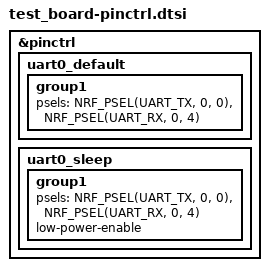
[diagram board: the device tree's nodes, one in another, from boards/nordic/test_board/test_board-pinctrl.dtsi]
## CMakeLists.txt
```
cmake_minimum_required(VERSION 3.20.0)

list(APPEND OVERLAY_CONFIG "$ENV{ZEPHYR_BASE}/../modules/lib/onomondo-softsim/overlay-softsim.conf")

find_package(Zephyr REQUIRED HINTS $ENV{ZEPHYR_BASE})

project(softsim_test)

target_sources(app PRIVATE src/main.c)
```

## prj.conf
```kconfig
### Onomondo SoftSIM ###
CONFIG_SOFTSIM_DEBUG=n
CONFIG_SOFTSIM_LOG_LEVEL_ERR=y
CONFIG_SOFTSIM_STATIC_PROFILE_ENABLE=y
# GSMA TS.48 USIM profile (standard test profile) replace with actual Onomondo profile
CONFIG_SOFTSIM_STATIC_PROFILE="01120829430512209610050214985437000000138663300320EF7A505140A7E8A25EA5368B52778CF70420E7DBC68622AB142A9C33881E20F42C5E0520B005031406ACF35099E61672E41747D10620D83BF18DA592DEC23855E83BC1A2BF340808393536310b1038353830343436370a2035393036333638383933383032333534"
### Onomondo SoftSIM ###

# Log Configurations
CONFIG_DEBUG=n
CONFIG_LOG=y
CONFIG_NRF_MODEM_LOG=n

# General Configurations
CONFIG_LOG_BUFFER_SIZE=5000
CONFIG_LOG_PROCESS_TRIGGER_THRESHOLD=5
CONFIG_LOG_DEFAULT_LEVEL=1

# Modem Configurations
CONFIG_NRF_MODEM_LIB=y

# NET Configurations
CONFIG_NETWORKING=y
CONFIG_NET_SOCKETS=y
CONFIG_NET_NATIVE=n
CONFIG_NET_SOCKETS_OFFLOAD=y
CONFIG_NET_SOCKETS_POSIX_NAMES=y

# LTE Configurations
CONFIG_LTE_LINK_CONTROL=y
CONFIG_LTE_LC_PSM_MODULE=y
CONFIG_LTE_LC_EDRX_MODULE=y
# Enable the neighbor cell measurement module to use the modem's neighbor cell measurement features
CONFIG_LTE_LC_NEIGHBOR_CELL_MEAS_MODULE=y
# Enable the LTE link control module to use the modem's PSM and eDRX features
CONFIG_LTE_PSM_REQ=y
CONFIG_LTE_EDRX_REQ=y

# AT host library
CONFIG_SERIAL=n
CONFIG_AT_HOST_LIBRARY=n
CONFIG_UART_INTERRUPT_DRIVEN=n

# Reduce the size of TF-M by disabling the PS
CONFIG_TFM_PARTITION_PROTECTED_STORAGE=n
CONFIG_PSA_CRYPTO_DRIVER_CC3XX=n

# Reduce the size of the TF-M partition
# when combined with static partitioning
CONFIG_PM_PARTITION_SIZE_TFM=0x10000

# The bootloader adds a small mcuboot_pad partition,
# whose size must be subtracted from the TF-M partition
#CONFIG_BOOTLOADER_MCUBOOT=y
#CONFIG_PM_PARTITION_SIZE_TFM=0xFE00

# Enable Segger RTT
CONFIG_USE_SEGGER_RTT=y

# Set RTT as the Zephyr logging backend
CONFIG_LOG_BACKEND_RTT=y

# Optional: Disable UART logging if you only want RTT
CONFIG_LOG_BACKEND_UART=n

# Increase RTT buffer size (if needed for large logs)
CONFIG_SEGGER_RTT_BUFFER_SIZE_UP=1024

# GNSS Configuration
CONFIG_LTE_NETWORK_MODE_LTE_M_NBIOT_GPS=y
# Newlib
# CONFIG_NEWLIB_LIBC=y
# # Enable printing of floating-points
# CONFIG_NEWLIB_LIBC_FLOAT_PRINTF=y
# CONFIG_FPU=y
# CONFIG_FPU_SHARING=y

# Network
CONFIG_POSIX_API=y

# Memory
CONFIG_HEAP_MEM_POOL_SIZE=4096
CONFIG_MAIN_STACK_SIZE=4096
```

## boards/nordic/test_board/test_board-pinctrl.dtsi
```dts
&pinctrl {
    uart0_default: uart0_default {
        group1 {
            psels = <NRF_PSEL(UART_TX, 0, 0)>,
                    <NRF_PSEL(UART_RX, 0, 4)>;
        };
    };

    uart0_sleep: uart0_sleep {
        group1 {
            psels = <NRF_PSEL(UART_TX, 0, 0)>,
                    <NRF_PSEL(UART_RX, 0, 4)>;
            low-power-enable;
        };
    };
};
```

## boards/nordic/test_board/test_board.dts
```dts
/dts-v1/;
#include <nordic/nrf9151_laca.dtsi>
#include "test_board-pinctrl.dtsi"
#include "test_board-partitioning.dtsi"

/ {
	chosen {
		zephyr,sram = &sram0_s;
		zephyr,flash = &flash0;
		zephyr,code-partition = &slot0_partition;
		zephyr,sram-secure-partition = &sram0_s;
		zephyr,sram-non-secure-partition = &sram0_ns;
	};
};

&uart0 {
    status = "okay";
    current-speed = <115200>;
    pinctrl-0 = <&uart0_default>;
    pinctrl-1 = <&uart0_sleep>;
    pinctrl-names = "default", "sleep";
};
```

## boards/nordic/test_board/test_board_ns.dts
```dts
/dts-v1/;
#include <nordic/nrf9151ns_laca.dtsi>
#include "test_board-pinctrl.dtsi"
#include "test_board-partitioning.dtsi"

/ {
	chosen {
		zephyr,flash = &flash0;
		zephyr,sram = &sram0_ns;
		zephyr,code-partition = &slot0_ns_partition;
	};
};

&uart0 {
    status = "okay";
    current-speed = <115200>;
    pinctrl-0 = <&uart0_default>;
    pinctrl-1 = <&uart0_sleep>;
    pinctrl-names = "default", "sleep";
};
```

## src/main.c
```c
#include <stdio.h>
#include <string.h>
#include <nrf_modem.h>
#include <nrf_modem_at.h>
#include <nrf_softsim.h>
#include <pm_config.h>
#include <modem/lte_lc.h>
#include <modem/nrf_modem_lib.h>
#include <modem/modem_info.h>

#include <zephyr/kernel.h>
#include <zephyr/net/socket.h>
#include <zephyr/drivers/clock_control.h>
#include <zephyr/drivers/clock_control/nrf_clock_control.h>
#include <zephyr/device.h>
#include <zephyr/drivers/uart.h>
#include <zephyr/logging/log.h>
#include <zephyr/logging/log_ctrl.h>
#include <zephyr/sys/reboot.h>
#include <zephyr/pm/pm.h>
// header for GNSS interface
#include <nrf_modem_gnss.h>

LOG_MODULE_REGISTER(softsim_sample, LOG_LEVEL_INF);

// semaphores
K_SEM_DEFINE(lte_connected, 0, 1); // semaphore to signal that the LTE connection is established
K_SEM_DEFINE(gnss_fix, 0, 1);      // Semaphore for GNSS fix

static void lte_handler(const struct lte_lc_evt *const evt);
static int server_connect(void);

static int client_fd;
static struct sockaddr_storage host_addr;
static struct k_work_delayable server_transmission_work;

// Add with your other global variables
static bool gnss_running = false;
static int32_t latitude_mdeg = 0;  // Latitude in millionths of a degree
static int32_t longitude_mdeg = 0; // Longitude in millionths of a degree
static uint32_t accuracy_cm = 0;   // Accuracy in centimeters
static bool has_fix = false;

// Signal quality tracking
static int16_t current_rsrp = 0;
static int16_t current_rsrq = 0;

static void request_signal_quality(void)
{
  int err;

  // Request neighbor cell measurements (includes signal strength)
  struct lte_lc_ncellmeas_params params = {0};
  err = lte_lc_neighbor_cell_measurement(&params);
  if (err)
  {
    LOG_WRN("Failed to request neighbor cell measurements: %d", err);
  }
  else
  {
    LOG_DBG("Neighbor cell measurement requested");
  }
}

static int request_gnss_fix(bool wait_for_fix)
{
  int err;

  // If GNSS is already running, do nothing
  if (gnss_running)
  {
    LOG_INF("GNSS is already running");
    return 0;
  }

  LOG_INF("Starting GNSS fix");

  // Clear the semaphore before starting
  k_sem_reset(&gnss_fix);

  // Start GNSS
  err = nrf_modem_gnss_start();
  if (err)
  {
    LOG_ERR("Failed to start GNSS: %d", err);
    return err;
  }

  gnss_running = true;

  if (wait_for_fix)
  {
    LOG_INF("Waiting for GNSS fix (timeout: 60s)");

    // Wait for a fix or timeout
    if (k_sem_take(&gnss_fix, K_SECONDS(60)) != 0)
    {
      LOG_WRN("GNSS fix timed out");

      // Stop GNSS to save power
      err = nrf_modem_gnss_stop();
      if (err)
      {
        LOG_ERR("Failed to stop GNSS: %d", err);
      }
      else
      {
        gnss_running = false;
      }

      return -ETIMEDOUT;
    }
  }

  return 0;
}

static void server_transmission_work_fn(struct k_work *work)
{
  // Get fresh signal quality before sending
  request_signal_quality();

  // Give a little time for signal quality to update
  k_sleep(K_MSEC(100));

  // Request GNSS location before sending
  LOG_INF("Requesting GNSS location fix");
  int gnss_err = request_gnss_fix(true); // true = wait for fix
  if (gnss_err)
  {
    LOG_WRN("Could not get GPS fix, sending last known position or zeros");
  }

  // Create JSON with signal quality
  char buffer[256];
  snprintf(buffer, sizeof(buffer),
           "{\"rsrp\":%d,\"rsrq\":%d,\"lat\":%d.%06d,\"lon\":%d.%06d,\"accuracy\":%d.%02d,\"has_fix\":%s}",
           current_rsrp, current_rsrq,
           latitude_mdeg / 1000000, abs(latitude_mdeg) % 1000000,
           longitude_mdeg / 1000000, abs(longitude_mdeg) % 1000000,
           accuracy_cm / 100, accuracy_cm % 100,
           has_fix ? "true" : "false");

  int err = send(client_fd, buffer, strlen(buffer), 0);

  if (err < 0)
  {
    LOG_ERR("Failed to transmit UDP packet, %d", errno);
    k_work_schedule(&server_transmission_work, K_SECONDS(2));
    return;
  }

  k_work_schedule(&server_transmission_work, K_SECONDS(180)); // Schedule next transmission in 3 minutes
}

static void work_init(void)
{
  k_work_init_delayable(&server_transmission_work, server_transmission_work_fn);
}

static void gnss_event_handler(int event)
{
  int err, num_satellites;
  struct nrf_modem_gnss_pvt_data_frame pvt_data;

  switch (event)
  {
  case NRF_MODEM_GNSS_EVT_PVT:
    num_satellites = 0;
    for (int i = 0; i < 12; i++)
    {
      if (pvt_data.sv[i].signal != 0)
      {
        LOG_INF("sv: %d, cn0: %d, signal: %d", pvt_data.sv[i].sv, pvt_data.sv[i].cn0, pvt_data.sv[i].signal);
        num_satellites++;
      }
    }
    LOG_INF("Searching. Current satellites: %d", num_satellites);
    err = nrf_modem_gnss_read(&pvt_data, sizeof(pvt_data), NRF_MODEM_GNSS_DATA_PVT);
    if (err)
    {
      LOG_ERR("nrf_modem_gnss_read failed, err %d", err);
      return;
    }
    if (pvt_data.flags & NRF_MODEM_GNSS_PVT_FLAG_FIX_VALID)
    {

      // We have a valid fix - convert float values to fixed-point integers
      latitude_mdeg = (int32_t)(pvt_data.latitude * 1000000);
      longitude_mdeg = (int32_t)(pvt_data.longitude * 1000000);
      accuracy_cm = (uint32_t)(pvt_data.accuracy * 100);
      has_fix = true;

      LOG_INF("GNSS Fix: Lat: %d.%06d, Lon: %d.%06d, Accuracy: %d.%02d m",
              latitude_mdeg / 1000000, abs(latitude_mdeg) % 1000000,
              longitude_mdeg / 1000000, abs(longitude_mdeg) % 1000000,
              accuracy_cm / 100, accuracy_cm % 100);

      // Signal that we have a fix
      k_sem_give(&gnss_fix);
      // After getting a fix, we can stop GNSS to save power
      err = nrf_modem_gnss_stop();
      if (err)
      {
        LOG_ERR("Failed to stop GNSS: %d", err);
      }
      else
      {
        gnss_running = false;
        LOG_INF("GNSS stopped after fix");
      }
    }
    /* Check for the flags indicating GNSS is blocked */
    if (pvt_data.flags & NRF_MODEM_GNSS_PVT_FLAG_DEADLINE_MISSED)
    {
      LOG_INF("GNSS blocked by LTE activity");
    }
    else if (pvt_data.flags & NRF_MODEM_GNSS_PVT_FLAG_NOT_ENOUGH_WINDOW_TIME)
    {
      LOG_INF("Insufficient GNSS time window");
    }
    break;

  case NRF_MODEM_GNSS_EVT_PERIODIC_WAKEUP:
    LOG_INF("GNSS has woken up");
    break;
  case NRF_MODEM_GNSS_EVT_SLEEP_AFTER_FIX:
    LOG_INF("GNSS enter sleep after fix");
    break;
  default:
    break;
  }
}

static int gnss_init(void)
{
  int err;

  // Register GNSS event handler
  err = nrf_modem_gnss_event_handler_set(gnss_event_handler);
  if (err)
  {
    LOG_ERR("Failed to set GNSS event handler: %d", err);
    return err;
  }

  // Set fix interval to single fix (0 = single, >0 = periodic interval in seconds)
  uint16_t fix_interval = 0; // Single fix
  err = nrf_modem_gnss_fix_interval_set(fix_interval);
  if (err)
  {
    LOG_ERR("Failed to set fix interval: %d", err);
  }

  // Set fix timeout to 60 seconds
  uint16_t fix_timeout = 60;
  err = nrf_modem_gnss_fix_retry_set(fix_timeout);
  if (err)
  {
    LOG_ERR("Failed to set fix timeout: %d", err);
  }

  LOG_INF("GNSS initialized successfully");
  return 0;
}

static void lte_handler(const struct lte_lc_evt *const evt)
{
  switch (evt->type)
  {
  case LTE_LC_EVT_NW_REG_STATUS:
    if ((evt->nw_reg_status != LTE_LC_NW_REG_REGISTERED_HOME) &&
        (evt->nw_reg_status != LTE_LC_NW_REG_REGISTERED_ROAMING))
    {
      break;
    }

    LOG_INF("Network registration status: %s",
            evt->nw_reg_status == LTE_LC_NW_REG_REGISTERED_HOME ? "Connected - home network" : "Connected - roaming");

    k_sem_give(&lte_connected);
    break;

  case LTE_LC_EVT_PSM_UPDATE:
    LOG_INF("PSM parameter update: TAU: %d, Active time: %d", evt->psm_cfg.tau, evt->psm_cfg.active_time);
    if (evt->psm_cfg.active_time == -1)
    {
      LOG_ERR("Network rejected PSM parameters. Failed to enable PSM");
    }
    break;
  case LTE_LC_EVT_EDRX_UPDATE:
  {
    char log_buf[60];
    ssize_t len;

    len = snprintf(log_buf, sizeof(log_buf), "eDRX parameter update: eDRX: %f, PTW: %f",
                   (double)evt->edrx_cfg.edrx, (double)evt->edrx_cfg.ptw);
    if (len > 0)
    {
      LOG_INF("%s\n", log_buf);
    }
    break;
  }
  case LTE_LC_EVT_RRC_UPDATE:
    LOG_INF("RRC mode: %s\n", evt->rrc_mode == LTE_LC_RRC_MODE_CONNECTED ? "Connected" : "Idle");
    break;
  case LTE_LC_EVT_CELL_UPDATE:
    LOG_INF("LTE cell changed: Cell ID: %d, Tracking area: %d", evt->cell.id, evt->cell.tac);
    break;

  // Add signal strength event handler
  case LTE_LC_EVT_NEIGHBOR_CELL_MEAS:
    LOG_INF("Neighbor cell measurement event received");

    if (evt->cells_info.current_cell.id != LTE_LC_CELL_EUTRAN_ID_INVALID)
    {
      // Current cell information is available
      current_rsrp = RSRP_IDX_TO_DBM(evt->cells_info.current_cell.rsrp);
      current_rsrq = RSRQ_IDX_TO_DB(evt->cells_info.current_cell.rsrq);

      LOG_INF("Current cell: ID=%d, RSRP=%d dBm, RSRQ=%d dB",
              evt->cells_info.current_cell.id,
              current_rsrp,
              current_rsrq);
    }

    if (evt->cells_info.ncells_count > 0)
    {
      // Neighboring cells information is available
      LOG_INF("Found %d neighbor cells", evt->cells_info.ncells_count);

      for (int i = 0; i < evt->cells_info.ncells_count; i++)
      {
        LOG_INF("Neighbor cell %d: PCI=%d, RSRP=%d dBm, RSRQ=%d dB",
                i + 1,
                evt->cells_info.neighbor_cells[i].phys_cell_id,
                RSRP_IDX_TO_DBM(evt->cells_info.neighbor_cells[i].rsrp),
                RSRQ_IDX_TO_DB(evt->cells_info.neighbor_cells[i].rsrq));
      }
    }
    break;

  default:
    break;
  }
}

static void modem_connect(void)
{
  int err = lte_lc_connect_async(lte_handler);
  if (err)
  {
    LOG_ERR("Connecting to LTE network failed, error: %d", err);
    return;
  }
}

static void server_disconnect(void)
{
  (void)close(client_fd);
}

static int server_init(void)
{
  struct sockaddr_in *server4 = ((struct sockaddr_in *)&host_addr);

  server4->sin_family = AF_INET;
  server4->sin_port = htons(4321);

  inet_pton(AF_INET, "1.2.3.4", &server4->sin_addr);

  return 0;
}

static int server_connect(void)
{
  int err;

  client_fd = socket(AF_INET, SOCK_DGRAM, IPPROTO_UDP);
  if (client_fd < 0)
  {
    LOG_ERR("Failed to create UDP socket: %d\n", errno);
    err = -errno;
    goto error;
  }

  err = connect(client_fd, (struct sockaddr *)&host_addr, sizeof(struct sockaddr_in));
  if (err < 0)
  {
    LOG_ERR("Connect failed : %d\n", errno);
    goto error;
  }

  return 0;

error:
  server_disconnect();
  return err;
}

int main(void)
{
  LOG_INF("SoftSIM sample started.");

  int32_t err = nrf_modem_lib_init();
  if (err)
  {
    LOG_ERR("Failed to initialize modem library, error: %d\n", err);
  }

  work_init();

  modem_connect();

  LOG_INF("Waiting for LTE connect event.\n");
  do
  {
  } while (k_sem_take(&lte_connected, K_SECONDS(10)));

  LOG_INF("LTE connected!\n");

  // Initialize GNSS
  err = gnss_init();
  if (err)
  {
    LOG_ERR("Failed to initialize GNSS: %d", err);
    // Continue anyway - we'll send without GPS data
  }
  // Request initial signal quality check
  request_signal_quality();

  err = server_init();
  if (err)
  {
    LOG_ERR("Not able to initialize UDP server connection\n");
    return -1;
  }

  err = server_connect();
  if (err)
  {
    LOG_ERR("Not able to connect to UDP server\n");
    return -1;
  }

  k_work_schedule(&server_transmission_work, K_NO_WAIT);
}
```

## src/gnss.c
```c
#include <stdio.h>
#include <ncs_version.h>
#include <zephyr/kernel.h>

#include <zephyr/logging/log.h>
#include <modem/nrf_modem_lib.h>
#include <modem/lte_lc.h>
#include <dk_buttons_and_leds.h>

/* STEP 4 - Include the header file for the GNSS interface */
#include <nrf_modem_gnss.h>

/* STEP 5 - Define the PVT data frame variable */
static struct nrf_modem_gnss_pvt_data_frame pvt_data;

/* STEP 12.1 - Declare helper variables to find the TTFF */
static int64_t gnss_start_time;
static bool first_fix = false;

static K_SEM_DEFINE(lte_connected, 0, 1);

LOG_MODULE_REGISTER(Lesson6_Exercise1, LOG_LEVEL_INF);

static int modem_configure(void)
{
    int err;

    LOG_INF("Initializing modem library");

    err = nrf_modem_lib_init();
    if (err) {
        LOG_ERR("Failed to initialize the modem library, error: %d", err);
        return err;
    }


    return 0;
}

/* STEP 6 - Define a function to log fix data in a readable format */
static void print_fix_data(struct nrf_modem_gnss_pvt_data_frame *pvt_data)
{
	LOG_INF("Latitude:       %.06f", pvt_data->latitude);
	LOG_INF("Longitude:      %.06f", pvt_data->longitude);
	LOG_INF("Altitude:       %.01f m", (double)pvt_data->altitude);
	LOG_INF("Time (UTC):     %02u:%02u:%02u.%03u",
	       pvt_data->datetime.hour,
	       pvt_data->datetime.minute,
	       pvt_data->datetime.seconds,
	       pvt_data->datetime.ms);
}

static void gnss_event_handler(int event)
{
    int err;

    switch (event) {
    /* STEP 7.1 - On a PVT event, confirm if PVT data is a valid fix */
    case NRF_MODEM_GNSS_EVT_PVT:
	LOG_INF("Searching...");
	/* STEP 15 - Print satellite information */
	err = nrf_modem_gnss_read(&pvt_data, sizeof(pvt_data), NRF_MODEM_GNSS_DATA_PVT);
	if (err) {
		LOG_ERR("nrf_modem_gnss_read failed, err %d", err);
		return;
	}
	if (pvt_data.flags & NRF_MODEM_GNSS_PVT_FLAG_FIX_VALID) {
		// dk_set_led_on(DK_LED1);
		print_fix_data(&pvt_data);
		/* STEP 12.3 - Print the time to first fix */
        if (!first_fix) {
            first_fix = true;
            // dk_set_led_on(DK_LED1);
            LOG_INF("Time to first fix: %2.1lld s", (k_uptime_get() - gnss_start_time)/1000);
        }
		return;
	}
	break;

    /* STEP 7.2 - Log when the GNSS sleeps and wakes up */
    case NRF_MODEM_GNSS_EVT_PERIODIC_WAKEUP:
	LOG_INF("GNSS has woken up");
	break;
    case NRF_MODEM_GNSS_EVT_SLEEP_AFTER_FIX:
	LOG_INF("GNSS enters sleep after fix");
	break;

    default:
        break;
    }
}

int main(void)
{
    int err;

    if (dk_leds_init() != 0) {
        LOG_ERR("Failed to initialize the LEDs Library");
    }

    err = modem_configure();
    if (err) {
        LOG_ERR("Failed to configure the modem");
        return 0;
    }

    /* STEP 8 - Activate only the GNSS stack */
    if (lte_lc_func_mode_set(LTE_LC_FUNC_MODE_ACTIVATE_GNSS) != 0) {
        LOG_ERR("Failed to activate GNSS functional mode");
        return;
    }	

    /* STEP 9 - Register the GNSS event handler */
    if (nrf_modem_gnss_event_handler_set(gnss_event_handler) != 0) {
        LOG_ERR("Failed to set GNSS event handler");
        return;
    }

    /* STEP 10 - Set the GNSS fix interval and GNSS fix retry period */
    if (nrf_modem_gnss_fix_interval_set(CONFIG_GNSS_PERIODIC_INTERVAL) != 0) {
        LOG_ERR("Failed to set GNSS fix interval");
        return;
    }
    
    if (nrf_modem_gnss_fix_retry_set(CONFIG_GNSS_PERIODIC_TIMEOUT) != 0) {
        LOG_ERR("Failed to set GNSS fix retry");
        return;
    }

    /* STEP 11 - Start the GNSS receiver*/
    LOG_INF("Starting GNSS");
    if (nrf_modem_gnss_start() != 0) {
        LOG_ERR("Failed to start GNSS");
        return;
    }

    /* STEP 12.2 - Log the current system uptime */
    gnss_start_time = k_uptime_get();

    return 0;
}
```
